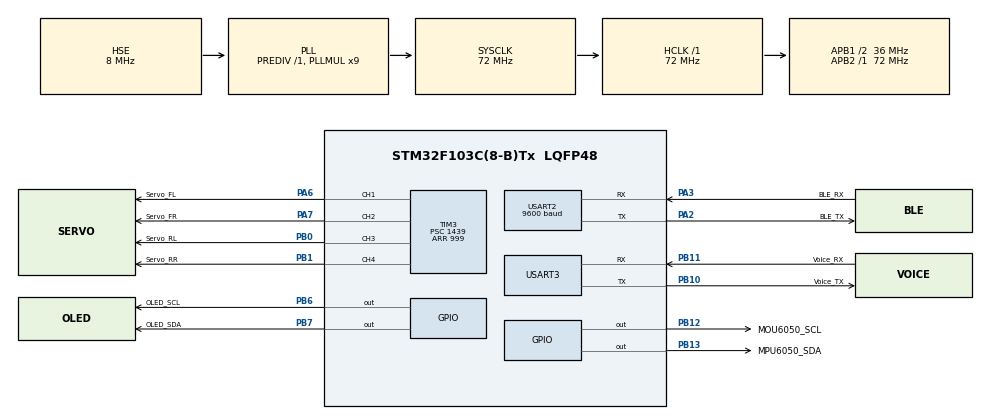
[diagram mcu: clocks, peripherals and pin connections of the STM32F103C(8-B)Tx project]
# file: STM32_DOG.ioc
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Dma.Request0=USART3_RX
Dma.Request1=USART2_RX
Dma.Request2=USART2_TX
Dma.Request3=USART3_TX
Dma.USART2_RX.1.Direction=DMA_PERIPH_TO_MEMORY
Dma.USART2_RX.1.Instance=DMA1_Channel6
Dma.USART2_RX.1.MemDataAlignment=DMA_MDATAALIGN_BYTE
Dma.USART2_RX.1.MemInc=DMA_MINC_ENABLE
Dma.USART2_RX.1.Mode=DMA_NORMAL
Dma.USART2_RX.1.PeriphDataAlignment=DMA_PDATAALIGN_BYTE
Dma.USART2_RX.1.PeriphInc=DMA_PINC_DISABLE
Dma.USART2_RX.1.Priority=DMA_PRIORITY_HIGH
Dma.USART2_TX.2.Direction=DMA_MEMORY_TO_PERIPH
Dma.USART2_TX.2.Instance=DMA1_Channel7
Dma.USART2_TX.2.MemDataAlignment=DMA_MDATAALIGN_BYTE
Dma.USART2_TX.2.MemInc=DMA_MINC_ENABLE
Dma.USART2_TX.2.Mode=DMA_NORMAL
Dma.USART2_TX.2.PeriphDataAlignment=DMA_PDATAALIGN_BYTE
Dma.USART2_TX.2.PeriphInc=DMA_PINC_DISABLE
Dma.USART2_TX.2.Priority=DMA_PRIORITY_LOW
Dma.USART3_RX.0.Direction=DMA_PERIPH_TO_MEMORY
Dma.USART3_RX.0.Instance=DMA1_Channel3
Dma.USART3_RX.0.MemDataAlignment=DMA_MDATAALIGN_BYTE
Dma.USART3_RX.0.MemInc=DMA_MINC_ENABLE
Dma.USART3_RX.0.Mode=DMA_NORMAL
Dma.USART3_RX.0.PeriphDataAlignment=DMA_PDATAALIGN_BYTE
Dma.USART3_RX.0.PeriphInc=DMA_PINC_DISABLE
Dma.USART3_RX.0.Priority=DMA_PRIORITY_MEDIUM
Dma.USART3_TX.3.Direction=DMA_MEMORY_TO_PERIPH
Dma.USART3_TX.3.Instance=DMA1_Channel2
Dma.USART3_TX.3.MemDataAlignment=DMA_MDATAALIGN_BYTE
Dma.USART3_TX.3.MemInc=DMA_MINC_ENABLE
Dma.USART3_TX.3.Mode=DMA_NORMAL
Dma.USART3_TX.3.PeriphDataAlignment=DMA_PDATAALIGN_BYTE
Dma.USART3_TX.3.PeriphInc=DMA_PINC_DISABLE
Dma.USART3_TX.3.Priority=DMA_PRIORITY_MEDIUM
FREERTOS.BinarySemaphores01=RxBleSem,Dynamic,NULL,Depleted;RxVoiceSem,Dynamic,NULL,Depleted;TxBleSem,Dynamic,NULL,Depleted;TxVoiceSem,Dynamic,NULL,Depleted
FREERTOS.Mutexes01=BleTxMutex,Dynamic,NULL,Available
FREERTOS.Queues01=action0Queue,10,uint8_t,0,Dynamic,NULL,NULL;sensorQueue,10,MPU6050_Data*,0,Dynamic,NULL,NULL;voiceQueue,16,uint16_t,0,Dynamic,NULL,NULL;BluetoothQueue,16,uint32_t,0,Dynamic,NULL,NULL
FREERTOS.Tasks01=ActionTask,25,512,StartActionTask,As weak,NULL,Dynamic,NULL,NULL;OLEDTask,8,256,StartOLEDTask,As external,NULL,Dynamic,NULL,NULL;SensorTask,24,256,StartSensorTask,As external,NULL,Dynamic,NULL,NULL;BluetoothComman,40,256,StartBluetoothCommandTask,As external,NULL,Dynamic,NULL,NULL;VoiceCommandTas,8,256,StartVoiceCommandTask,As external,NULL,Dynamic,NULL,NULL
FREERTOS.configTOTAL_HEAP_SIZE=8192
Mcu.Family=STM32F1
Mcu.Name=STM32F103C(8-B)Tx
Mcu.Package=LQFP48
NVIC.DMA1_Channel2_IRQn=true\:5\:0\:false\:false\:true\:true\:false\:true\:true
NVIC.DMA1_Channel3_IRQn=true\:5\:0\:false\:false\:true\:true\:false\:true\:true
NVIC.DMA1_Channel6_IRQn=true\:5\:0\:false\:false\:true\:true\:false\:true\:true
NVIC.DMA1_Channel7_IRQn=true\:5\:0\:false\:false\:true\:true\:false\:true\:true
NVIC.PriorityGroup=NVIC_PRIORITYGROUP_4
NVIC.TIM4_IRQn=true\:15\:0\:false\:false\:true\:false\:false\:true\:true
NVIC.TimeBase=TIM4_IRQn
NVIC.TimeBaseIP=TIM4
NVIC.USART2_IRQn=true\:5\:0\:false\:false\:true\:true\:true\:true\:true
NVIC.USART3_IRQn=true\:6\:0\:true\:false\:true\:true\:true\:true\:true
PA13.Mode=Serial_Wire
PA13.Signal=SYS_JTMS-SWDIO
PA14.Mode=Serial_Wire
PA14.Signal=SYS_JTCK-SWCLK
PA2.GPIO_Label=BLE_TX
PA2.Mode=Asynchronous
PA2.Signal=USART2_TX
PA3.GPIO_Label=BLE_RX
PA3.Mode=Asynchronous
PA3.Signal=USART2_RX
PA6.GPIO_Label=Servo_FL
PA6.Signal=S_TIM3_CH1
PA7.GPIO_Label=Servo_FR
PA7.Signal=S_TIM3_CH2
PB0.GPIO_Label=Servo_RL
PB0.Signal=S_TIM3_CH3
PB1.GPIO_Label=Servo_RR
PB1.Signal=S_TIM3_CH4
PB10.GPIO_Label=Voice_TX
PB10.Mode=Asynchronous
PB10.Signal=USART3_TX
PB11.GPIO_Label=Voice_RX
PB11.Mode=Asynchronous
PB11.Signal=USART3_RX
PB12.GPIO_Label=MOU6050_SCL
PB12.GPIO_ModeDefaultOutputPP=GPIO_MODE_OUTPUT_OD
PB12.GPIO_PuPd=GPIO_PULLUP
PB12.Signal=GPIO_Output
PB13.GPIO_Label=MPU6050_SDA
PB13.GPIO_ModeDefaultOutputPP=GPIO_MODE_OUTPUT_OD
PB13.GPIO_PuPd=GPIO_PULLUP
PB13.Signal=GPIO_Output
PB6.GPIO_Label=OLED_SCL
PB6.GPIO_ModeDefaultOutputPP=GPIO_MODE_OUTPUT_OD
PB6.GPIO_PuPd=GPIO_PULLUP
PB6.Signal=GPIO_Output
PB7.GPIO_Label=OLED_SDA
PB7.GPIO_ModeDefaultOutputPP=GPIO_MODE_OUTPUT_OD
PB7.GPIO_PuPd=GPIO_PULLUP
PB7.Signal=GPIO_Output
PD0-OSC_IN.Mode=HSE-External-Oscillator
PD0-OSC_IN.Signal=RCC_OSC_IN
PD1-OSC_OUT.Mode=HSE-External-Oscillator
PD1-OSC_OUT.Signal=RCC_OSC_OUT
ProjectManager.HeapSize=0x200
ProjectManager.StackSize=0x400
ProjectManager.TargetToolchain=CMake
RCC.AHBFreq_Value=72000000
RCC.APB1CLKDivider=RCC_HCLK_DIV2
RCC.APB1Freq_Value=36000000
RCC.APB1TimFreq_Value=72000000
RCC.APB2Freq_Value=72000000
RCC.APB2TimFreq_Value=72000000
RCC.HCLKFreq_Value=72000000
RCC.PLLMUL=RCC_PLL_MUL9
RCC.PLLSourceVirtual=RCC_PLLSOURCE_HSE
RCC.SYSCLKFreq_VALUE=72000000
RCC.SYSCLKSource=RCC_SYSCLKSOURCE_PLLCLK
RCC.USBFreq_Value=72000000
SH.S_TIM3_CH1.0=TIM3_CH1,PWM Generation1 CH1
SH.S_TIM3_CH2.0=TIM3_CH2,PWM Generation2 CH2
SH.S_TIM3_CH3.0=TIM3_CH3,PWM Generation3 CH3
SH.S_TIM3_CH4.0=TIM3_CH4,PWM Generation4 CH4
TIM3.AutoReloadPreload=TIM_AUTORELOAD_PRELOAD_ENABLE
TIM3.Channel-PWM\ Generation1\ CH1=TIM_CHANNEL_1
TIM3.Channel-PWM\ Generation2\ CH2=TIM_CHANNEL_2
TIM3.Channel-PWM\ Generation3\ CH3=TIM_CHANNEL_3
TIM3.Channel-PWM\ Generation4\ CH4=TIM_CHANNEL_4
TIM3.Period=999
TIM3.Prescaler=1439
TIM3.Pulse-PWM\ Generation2\ CH2=0
USART2.BaudRate=9600
USART2.VirtualMode=VM_ASYNC
USART3.VirtualMode=VM_ASYNC
VP_FREERTOS_VS_CMSIS_V2.Mode=CMSIS_V2
VP_SYS_VS_tim4.Mode=TIM4
board=custom

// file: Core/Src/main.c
/* USER CODE BEGIN Header */
/**
  ******************************************************************************
  * @file           : main.c
  * @brief          : Main program body
  ******************************************************************************
  * @attention
  *
  * Copyright (c) 2026 STMicroelectronics.
  * All rights reserved.
  *
  * This software is licensed under terms that can be found in the LICENSE file
  * in the root directory of this software component.
  * If no LICENSE file comes with this software, it is provided AS-IS.
  *
  ******************************************************************************
  */
/* USER CODE END Header */
#include "main.h"
#include "cmsis_os.h"
#include "dma.h"
#include "tim.h"
#include "usart.h"
#include "gpio.h"

void SystemClock_Config(void);
void MX_FREERTOS_Init(void);

int main(void)
{

  /* MCU Configuration--------------------------------------------------------*/

  /* Reset of all peripherals, Initializes the Flash interface and the Systick. */
  HAL_Init();

  /* Configure the system clock */
  SystemClock_Config();

  /* Initialize all configured peripherals */
  MX_GPIO_Init();
  MX_DMA_Init();
  MX_TIM3_Init();
  MX_USART2_UART_Init();
  MX_USART3_UART_Init();
  /* USER CODE BEGIN 2 */
  /* Onboard LED (PC13) used as activity indicator, active-low on Blue Pill */

  /* USER CODE END 2 */

  /* Init scheduler */
  osKernelInitialize();

  /* Call init function for freertos objects (in cmsis_os2.c) */
  MX_FREERTOS_Init();

  /* Start scheduler */
  osKernelStart();

  /* We should never get here as control is now taken by the scheduler */

  /* Infinite loop */
  while (1)
  {

  }
}

void SystemClock_Config(void)
{
  RCC_OscInitTypeDef RCC_OscInitStruct = {0};
  RCC_ClkInitTypeDef RCC_ClkInitStruct = {0};

  /** Initializes the RCC Oscillators according to the specified parameters
  * in the RCC_OscInitTypeDef structure.
  */
  RCC_OscInitStruct.OscillatorType = RCC_OSCILLATORTYPE_HSE;
  RCC_OscInitStruct.HSEState = RCC_HSE_ON;
  RCC_OscInitStruct.HSEPredivValue = RCC_HSE_PREDIV_DIV1;
  RCC_OscInitStruct.HSIState = RCC_HSI_ON;
  RCC_OscInitStruct.PLL.PLLState = RCC_PLL_ON;
  RCC_OscInitStruct.PLL.PLLSource = RCC_PLLSOURCE_HSE;
  RCC_OscInitStruct.PLL.PLLMUL = RCC_PLL_MUL9;
  if (HAL_RCC_OscConfig(&RCC_OscInitStruct) != HAL_OK)
  {
    Error_Handler();
  }

  /** Initializes the CPU, AHB and APB buses clocks
  */
  RCC_ClkInitStruct.ClockType = RCC_CLOCKTYPE_HCLK|RCC_CLOCKTYPE_SYSCLK
                              |RCC_CLOCKTYPE_PCLK1|RCC_CLOCKTYPE_PCLK2;
  RCC_ClkInitStruct.SYSCLKSource = RCC_SYSCLKSOURCE_PLLCLK;
  RCC_ClkInitStruct.AHBCLKDivider = RCC_SYSCLK_DIV1;
  RCC_ClkInitStruct.APB1CLKDivider = RCC_HCLK_DIV2;
  RCC_ClkInitStruct.APB2CLKDivider = RCC_HCLK_DIV1;

  if (HAL_RCC_ClockConfig(&RCC_ClkInitStruct, FLASH_LATENCY_2) != HAL_OK)
  {
    Error_Handler();
  }
}

void HAL_TIM_PeriodElapsedCallback(TIM_HandleTypeDef *htim)
{
  if (htim->Instance == TIM4)
  {
    HAL_IncTick();
  }
}

void Error_Handler(void)
{
  __disable_irq();
  while (1)
  {
  }
}

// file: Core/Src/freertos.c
/* USER CODE BEGIN Header */
/**
  ******************************************************************************
  * File Name          : freertos.c
  * Description        : Code for freertos applications
  ******************************************************************************
  * @attention
  *
  * Copyright (c) 2026 STMicroelectronics.
  * All rights reserved.
  *
  * This software is licensed under terms that can be found in the LICENSE file
  * in the root directory of this software component.
  * If no LICENSE file comes with this software, it is provided AS-IS.
  *
  ******************************************************************************
  */
/* USER CODE END Header */

#include "FreeRTOS.h"
#include "task.h"
#include "main.h"
#include "cmsis_os.h"

/* Definitions for ActionTask */
osThreadId_t ActionTaskHandle;
const osThreadAttr_t ActionTask_attributes = {
  .name = "ActionTask",
  .stack_size = 512 * 4,
  .priority = (osPriority_t) osPriorityNormal1,
};
/* Definitions for OLEDTask */
osThreadId_t OLEDTaskHandle;
const osThreadAttr_t OLEDTask_attributes = {
  .name = "OLEDTask",
  .stack_size = 256 * 4,
  .priority = (osPriority_t) osPriorityLow,
};
/* Definitions for SensorTask */
osThreadId_t SensorTaskHandle;
const osThreadAttr_t SensorTask_attributes = {
  .name = "SensorTask",
  .stack_size = 256 * 4,
  .priority = (osPriority_t) osPriorityNormal,
};
/* Definitions for BluetoothComman */
osThreadId_t BluetoothCommanHandle;
const osThreadAttr_t BluetoothComman_attributes = {
  .name = "BluetoothComman",
  .stack_size = 256 * 4,
  .priority = (osPriority_t) osPriorityHigh,
};
/* Definitions for VoiceCommandTas */
osThreadId_t VoiceCommandTasHandle;
const osThreadAttr_t VoiceCommandTas_attributes = {
  .name = "VoiceCommandTas",
  .stack_size = 256 * 4,
  .priority = (osPriority_t) osPriorityLow,
};
/* Definitions for action0Queue */
osMessageQueueId_t action0QueueHandle;
const osMessageQueueAttr_t action0Queue_attributes = {
  .name = "action0Queue"
};
/* Definitions for sensorQueue */
osMessageQueueId_t sensorQueueHandle;
const osMessageQueueAttr_t sensorQueue_attributes = {
  .name = "sensorQueue"
};
/* Definitions for voiceQueue */
osMessageQueueId_t voiceQueueHandle;
const osMessageQueueAttr_t voiceQueue_attributes = {
  .name = "voiceQueue"
};
/* Definitions for BluetoothQueue */
osMessageQueueId_t BluetoothQueueHandle;
const osMessageQueueAttr_t BluetoothQueue_attributes = {
  .name = "BluetoothQueue"
};
/* Definitions for BleTxMutex */
osMutexId_t BleTxMutexHandle;
const osMutexAttr_t BleTxMutex_attributes = {
  .name = "BleTxMutex"
};
/* Definitions for RxBleSem */
osSemaphoreId_t RxBleSemHandle;
const osSemaphoreAttr_t RxBleSem_attributes = {
  .name = "RxBleSem"
};
/* Definitions for RxVoiceSem */
osSemaphoreId_t RxVoiceSemHandle;
const osSemaphoreAttr_t RxVoiceSem_attributes = {
  .name = "RxVoiceSem"
};
/* Definitions for TxBleSem */
osSemaphoreId_t TxBleSemHandle;
const osSemaphoreAttr_t TxBleSem_attributes = {
  .name = "TxBleSem"
};
/* Definitions for TxVoiceSem */
osSemaphoreId_t TxVoiceSemHandle;
const osSemaphoreAttr_t TxVoiceSem_attributes = {
  .name = "TxVoiceSem"
};

void StartActionTask(void *argument);
extern void StartOLEDTask(void *argument);
extern void StartSensorTask(void *argument);
extern void StartBluetoothCommandTask(void *argument);
extern void StartVoiceCommandTask(void *argument);

void MX_FREERTOS_Init(void); /* (MISRA C 2004 rule 8.1) */

void MX_FREERTOS_Init(void) {
  /* Create the mutex(es) */
  /* creation of BleTxMutex */
  BleTxMutexHandle = osMutexNew(&BleTxMutex_attributes);

  /* Create the semaphores(s) */
  /* creation of RxBleSem */
  RxBleSemHandle = osSemaphoreNew(1, 0, &RxBleSem_attributes);

  /* creation of RxVoiceSem */
  RxVoiceSemHandle = osSemaphoreNew(1, 0, &RxVoiceSem_attributes);

  /* creation of TxBleSem */
  TxBleSemHandle = osSemaphoreNew(1, 0, &TxBleSem_attributes);

  /* creation of TxVoiceSem */
  TxVoiceSemHandle = osSemaphoreNew(1, 0, &TxVoiceSem_attributes);

  /* Create the queue(s) */
  /* creation of action0Queue */
  action0QueueHandle = osMessageQueueNew (10, sizeof(uint8_t), &action0Queue_attributes);

  /* creation of sensorQueue */
  sensorQueueHandle = osMessageQueueNew (10, sizeof(MPU6050_Data*), &sensorQueue_attributes);

  /* creation of voiceQueue */
  voiceQueueHandle = osMessageQueueNew (16, sizeof(uint16_t), &voiceQueue_attributes);

  /* creation of BluetoothQueue */
  BluetoothQueueHandle = osMessageQueueNew (16, sizeof(uint32_t), &BluetoothQueue_attributes);

  /* Create the thread(s) */
  /* creation of ActionTask */
  ActionTaskHandle = osThreadNew(StartActionTask, NULL, &ActionTask_attributes);

  /* creation of OLEDTask */
  OLEDTaskHandle = osThreadNew(StartOLEDTask, NULL, &OLEDTask_attributes);

  /* creation of SensorTask */
  SensorTaskHandle = osThreadNew(StartSensorTask, NULL, &SensorTask_attributes);

  /* creation of BluetoothComman */
  BluetoothCommanHandle = osThreadNew(StartBluetoothCommandTask, NULL, &BluetoothComman_attributes);

  /* creation of VoiceCommandTas */
  VoiceCommandTasHandle = osThreadNew(StartVoiceCommandTask, NULL, &VoiceCommandTas_attributes);

}

__weak void StartActionTask(void *argument)
{
  for(;;)
  {
    osDelay(1);
  }
}
